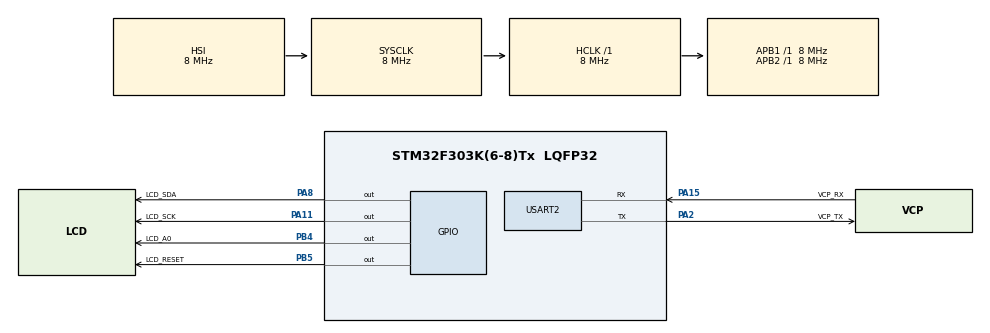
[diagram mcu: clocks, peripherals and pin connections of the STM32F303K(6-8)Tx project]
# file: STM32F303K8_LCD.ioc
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Mcu.Family=STM32F3
Mcu.Name=STM32F303K(6-8)Tx
Mcu.Package=LQFP32
NVIC.PriorityGroup=NVIC_PRIORITYGROUP_4
NVIC.TIM3_IRQn=true\:0\:0\:false\:false\:true\:true\:true
PA11.GPIO_Label=LCD_SCK
PA11.Signal=GPIO_Output
PA13.GPIO_Label=SWDIO
PA13.Mode=Serial_Wire
PA13.Signal=SYS_JTMS-SWDIO
PA14.GPIO_Label=SWCLK
PA14.Mode=Serial_Wire
PA14.Signal=SYS_JTCK-SWCLK
PA15.GPIO_Label=VCP_RX
PA15.Mode=Asynchronous
PA15.Signal=USART2_RX
PA2.GPIO_Label=VCP_TX
PA2.Mode=Asynchronous
PA2.Signal=USART2_TX
PA8.GPIO_Label=LCD_SDA
PA8.Signal=GPIO_Output
PB4.GPIO_Label=LCD_A0
PB4.Signal=GPIO_Output
PB5.GPIO_Label=LCD_RESET
PB5.Signal=GPIO_Output
PF0\ /\ OSC_IN.GPIO_Label=MCO
PF0\ /\ OSC_IN.Mode=HSE-External-Clock-Source
PF0\ /\ OSC_IN.Signal=RCC_OSC_IN
ProjectManager.HeapSize=0x200
ProjectManager.StackSize=0x400
ProjectManager.TargetToolchain=Makefile
RCC.AHBFreq_Value=8000000
RCC.APB1Freq_Value=8000000
RCC.APB2Freq_Value=8000000
RCC.CortexFreq_Value=8000000
RCC.HSE_VALUE=8000000
RCC.HSI_VALUE=8000000
RCC.SYSCLKFreq_VALUE=8000000
TIM1.Channel-Output\ Compare1\ No\ Output=TIM_CHANNEL_1
TIM3.Channel-Output\ Compare1\ No\ Output=TIM_CHANNEL_1
USART2.VirtualMode-Asynchronous=VM_ASYNC
VP_TIM1_VS_ClockSourceINT.Mode=Internal
VP_TIM1_VS_ClockSourceITR.Mode=TriggerSource_ITR0
VP_TIM1_VS_no_output1.Mode=Output Compare1 No Output
VP_TIM3_VS_ClockSourceINT.Mode=Internal
VP_TIM3_VS_no_output1.Mode=Output Compare1 No Output
board=NUCLEO-F303K8

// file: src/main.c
/* USER CODE BEGIN Header */
/**
  ******************************************************************************
  * @file           : main.c
  * @brief          : Main program body
  ******************************************************************************
  * @attention
  *
  * <h2><center>&copy; Copyright (c) 2020 STMicroelectronics.
  * All rights reserved.</center></h2>
  *
  * This software component is licensed by ST under BSD 3-Clause license,
  * the "License"; You may not use this file except in compliance with the
  * License. You may obtain a copy of the License at:
  *                        opensource.org/licenses/BSD-3-Clause
  *
  ******************************************************************************
  */
/* USER CODE END Header */

#include "main.h"

TIM_HandleTypeDef htim1;
TIM_HandleTypeDef htim3;

UART_HandleTypeDef huart2;

/* USER CODE BEGIN PV */
uint8_t led=0;
uint8_t scl=0;
uint8_t sda=0;
uint8_t pixy = 0;
uint8_t pixx = 0;
uint8_t csx = 1;
uint8_t pix_idx = 0;
uint8_t pix_buffer_idx = 0;
uint16_t pix_buffer=0;

/* USER CODE END PV */

void SystemClock_Config(void);
static void MX_GPIO_Init(void);
static void MX_TIM1_Init(void);
static void MX_USART2_UART_Init(void);
static void MX_TIM3_Init(void);

/* USER CODE BEGIN 0 */
// Definition of pixel info of color bar
PixInfo_t pixInfos0[] = { {160, 0x0} };
PixInfo_t pixInfos1[] = { {3, 0x0}, {22, 0xb5b6}, {22, 0xb5a1}, {22, 0xdb6}, {22, 0xda1}, {22, 0xb096}, {22, 0xb061}, {22, 0x876}, {3, 0x0} };
PixInfo_t pixInfos2[] = { {3, 0x0}, {22, 0x876}, {22, 0x1082}, {22, 0xb096}, {22, 0x1082}, {22, 0xdb6}, {22, 0x1082}, {22, 0xb5b6}, {3, 0x0} };
PixInfo_t pixInfos3[] = { {3, 0x0}, {27, 0x8e8}, {28, 0xef5d}, {27, 0x280b}, {28, 0x1082}, {7, 0x20}, {8, 0x1082}, {7, 0x18c3}, {22, 0x1082}, {3, 0x0} };
PixInfo_t pixInfos4[] = { {160, 0x0} };

LineInfo_t lineInfos[] = {{1, sizeof(pixInfos0)/sizeof(PixInfo_t), pixInfos0}, {84, sizeof(pixInfos1)/sizeof(PixInfo_t), pixInfos1}, {8, sizeof(pixInfos2)/sizeof(PixInfo_t), pixInfos2},{34, sizeof(pixInfos3)/sizeof(PixInfo_t), pixInfos3},{1, sizeof(pixInfos4)/sizeof(PixInfo_t), pixInfos4}};
/* USER CODE END 0 */

int main(void)
{

  /* MCU Configuration--------------------------------------------------------*/

  /* Reset of all peripherals, Initializes the Flash interface and the Systick. */
  HAL_Init();

  /* Configure the system clock */
  SystemClock_Config();

  /* Initialize all configured peripherals */
  MX_GPIO_Init();
  MX_TIM1_Init();
  MX_USART2_UART_Init();
  MX_TIM3_Init();
  /* USER CODE BEGIN 2 */
  HAL_TIM_Base_Start_IT(&htim3); // Begin timer(TMR3) interrupt
  /* disable it HAL_TIM_Base_Stop_IT(&htim3); */
  /* USER CODE END 2 */

  /* Infinite loop */
  while (1)
  {

  }
}

void SystemClock_Config(void)
{
  RCC_OscInitTypeDef RCC_OscInitStruct = {0};
  RCC_ClkInitTypeDef RCC_ClkInitStruct = {0};
  RCC_PeriphCLKInitTypeDef PeriphClkInit = {0};

  /** Initializes the CPU, AHB and APB busses clocks
  */
  RCC_OscInitStruct.OscillatorType = RCC_OSCILLATORTYPE_HSI;
  RCC_OscInitStruct.HSIState = RCC_HSI_ON;
  RCC_OscInitStruct.HSICalibrationValue = RCC_HSICALIBRATION_DEFAULT;
  RCC_OscInitStruct.PLL.PLLState = RCC_PLL_NONE;
  if (HAL_RCC_OscConfig(&RCC_OscInitStruct) != HAL_OK)
  {
    Error_Handler();
  }
  /** Initializes the CPU, AHB and APB busses clocks
  */
  RCC_ClkInitStruct.ClockType = RCC_CLOCKTYPE_HCLK|RCC_CLOCKTYPE_SYSCLK
                              |RCC_CLOCKTYPE_PCLK1|RCC_CLOCKTYPE_PCLK2;
  RCC_ClkInitStruct.SYSCLKSource = RCC_SYSCLKSOURCE_HSI;
  RCC_ClkInitStruct.AHBCLKDivider = RCC_SYSCLK_DIV1;
  RCC_ClkInitStruct.APB1CLKDivider = RCC_HCLK_DIV1;
  RCC_ClkInitStruct.APB2CLKDivider = RCC_HCLK_DIV1;

  if (HAL_RCC_ClockConfig(&RCC_ClkInitStruct, FLASH_LATENCY_0) != HAL_OK)
  {
    Error_Handler();
  }
  PeriphClkInit.PeriphClockSelection = RCC_PERIPHCLK_TIM1;
  PeriphClkInit.Tim1ClockSelection = RCC_TIM1CLK_HCLK;
  if (HAL_RCCEx_PeriphCLKConfig(&PeriphClkInit) != HAL_OK)
  {
    Error_Handler();
  }
}

static void MX_TIM1_Init(void)
{

  TIM_ClockConfigTypeDef sClockSourceConfig = {0};
  TIM_SlaveConfigTypeDef sSlaveConfig = {0};
  TIM_MasterConfigTypeDef sMasterConfig = {0};
  TIM_OC_InitTypeDef sConfigOC = {0};
  TIM_BreakDeadTimeConfigTypeDef sBreakDeadTimeConfig = {0};

  htim1.Instance = TIM1;
  htim1.Init.Prescaler = 0;
  htim1.Init.CounterMode = TIM_COUNTERMODE_UP;
  htim1.Init.Period = 0;
  htim1.Init.ClockDivision = TIM_CLOCKDIVISION_DIV1;
  htim1.Init.RepetitionCounter = 0;
  htim1.Init.AutoReloadPreload = TIM_AUTORELOAD_PRELOAD_DISABLE;
  if (HAL_TIM_Base_Init(&htim1) != HAL_OK)
  {
    Error_Handler();
  }
  sClockSourceConfig.ClockSource = TIM_CLOCKSOURCE_INTERNAL;
  if (HAL_TIM_ConfigClockSource(&htim1, &sClockSourceConfig) != HAL_OK)
  {
    Error_Handler();
  }
  if (HAL_TIM_OC_Init(&htim1) != HAL_OK)
  {
    Error_Handler();
  }
  sSlaveConfig.SlaveMode = TIM_SLAVEMODE_DISABLE;
  sSlaveConfig.InputTrigger = TIM_TS_ITR0;
  if (HAL_TIM_SlaveConfigSynchro(&htim1, &sSlaveConfig) != HAL_OK)
  {
    Error_Handler();
  }
  sMasterConfig.MasterOutputTrigger = TIM_TRGO_RESET;
  sMasterConfig.MasterOutputTrigger2 = TIM_TRGO2_RESET;
  sMasterConfig.MasterSlaveMode = TIM_MASTERSLAVEMODE_DISABLE;
  if (HAL_TIMEx_MasterConfigSynchronization(&htim1, &sMasterConfig) != HAL_OK)
  {
    Error_Handler();
  }
  sConfigOC.OCMode = TIM_OCMODE_TIMING;
  sConfigOC.Pulse = 0;
  sConfigOC.OCPolarity = TIM_OCPOLARITY_HIGH;
  sConfigOC.OCNPolarity = TIM_OCNPOLARITY_HIGH;
  sConfigOC.OCFastMode = TIM_OCFAST_DISABLE;
  sConfigOC.OCIdleState = TIM_OCIDLESTATE_RESET;
  sConfigOC.OCNIdleState = TIM_OCNIDLESTATE_RESET;
  if (HAL_TIM_OC_ConfigChannel(&htim1, &sConfigOC, TIM_CHANNEL_1) != HAL_OK)
  {
    Error_Handler();
  }
  sBreakDeadTimeConfig.OffStateRunMode = TIM_OSSR_DISABLE;
  sBreakDeadTimeConfig.OffStateIDLEMode = TIM_OSSI_DISABLE;
  sBreakDeadTimeConfig.LockLevel = TIM_LOCKLEVEL_OFF;
  sBreakDeadTimeConfig.DeadTime = 0;
  sBreakDeadTimeConfig.BreakState = TIM_BREAK_DISABLE;
  sBreakDeadTimeConfig.BreakPolarity = TIM_BREAKPOLARITY_HIGH;
  sBreakDeadTimeConfig.BreakFilter = 0;
  sBreakDeadTimeConfig.Break2State = TIM_BREAK2_DISABLE;
  sBreakDeadTimeConfig.Break2Polarity = TIM_BREAK2POLARITY_HIGH;
  sBreakDeadTimeConfig.Break2Filter = 0;
  sBreakDeadTimeConfig.AutomaticOutput = TIM_AUTOMATICOUTPUT_DISABLE;
  if (HAL_TIMEx_ConfigBreakDeadTime(&htim1, &sBreakDeadTimeConfig) != HAL_OK)
  {
    Error_Handler();
  }

}

static void MX_TIM3_Init(void)
{

  TIM_ClockConfigTypeDef sClockSourceConfig = {0};
  TIM_MasterConfigTypeDef sMasterConfig = {0};
  TIM_OC_InitTypeDef sConfigOC = {0};

  htim3.Instance = TIM3;
  htim3.Init.Prescaler = 7999;
  htim3.Init.CounterMode = TIM_COUNTERMODE_UP;
  htim3.Init.Period = 999;
  htim3.Init.ClockDivision = TIM_CLOCKDIVISION_DIV1;
  htim3.Init.AutoReloadPreload = TIM_AUTORELOAD_PRELOAD_DISABLE;
  if (HAL_TIM_Base_Init(&htim3) != HAL_OK)
  {
    Error_Handler();
  }
  sClockSourceConfig.ClockSource = TIM_CLOCKSOURCE_INTERNAL;
  if (HAL_TIM_ConfigClockSource(&htim3, &sClockSourceConfig) != HAL_OK)
  {
    Error_Handler();
  }
  if (HAL_TIM_OC_Init(&htim3) != HAL_OK)
  {
    Error_Handler();
  }
  sMasterConfig.MasterOutputTrigger = TIM_TRGO_RESET;
  sMasterConfig.MasterSlaveMode = TIM_MASTERSLAVEMODE_DISABLE;
  if (HAL_TIMEx_MasterConfigSynchronization(&htim3, &sMasterConfig) != HAL_OK)
  {
    Error_Handler();
  }
  sConfigOC.OCMode = TIM_OCMODE_TIMING;
  sConfigOC.Pulse = 0;
  sConfigOC.OCPolarity = TIM_OCPOLARITY_HIGH;
  sConfigOC.OCFastMode = TIM_OCFAST_DISABLE;
  if (HAL_TIM_OC_ConfigChannel(&htim3, &sConfigOC, TIM_CHANNEL_1) != HAL_OK)
  {
    Error_Handler();
  }

}

static void MX_USART2_UART_Init(void)
{

  huart2.Instance = USART2;
  huart2.Init.BaudRate = 38400;
  huart2.Init.WordLength = UART_WORDLENGTH_8B;
  huart2.Init.StopBits = UART_STOPBITS_1;
  huart2.Init.Parity = UART_PARITY_NONE;
  huart2.Init.Mode = UART_MODE_TX_RX;
  huart2.Init.HwFlowCtl = UART_HWCONTROL_NONE;
  huart2.Init.OverSampling = UART_OVERSAMPLING_16;
  huart2.Init.OneBitSampling = UART_ONE_BIT_SAMPLE_DISABLE;
  huart2.AdvancedInit.AdvFeatureInit = UART_ADVFEATURE_NO_INIT;
  if (HAL_UART_Init(&huart2) != HAL_OK)
  {
    Error_Handler();
  }

}

static void MX_GPIO_Init(void)
{
  GPIO_InitTypeDef GPIO_InitStruct = {0};

  /* GPIO Ports Clock Enable */
  __HAL_RCC_GPIOF_CLK_ENABLE();
  __HAL_RCC_GPIOA_CLK_ENABLE();
  __HAL_RCC_GPIOB_CLK_ENABLE();

  /*Configure GPIO pin Output Level */
  HAL_GPIO_WritePin(GPIOA, LCD_SDA_Pin|LCD_SCK_Pin, GPIO_PIN_RESET);

  /*Configure GPIO pin Output Level */
  HAL_GPIO_WritePin(GPIOB, LCD_A0_Pin|LCD_RESET_Pin|GPIO_PIN_3, GPIO_PIN_RESET);

  /*Configure GPIO pins : LCD_SDA_Pin LCD_SCK_Pin */
  GPIO_InitStruct.Pin = LCD_SDA_Pin|LCD_SCK_Pin;
  GPIO_InitStruct.Mode = GPIO_MODE_OUTPUT_PP;
  GPIO_InitStruct.Pull = GPIO_NOPULL;
  GPIO_InitStruct.Speed = GPIO_SPEED_FREQ_LOW;
  HAL_GPIO_Init(GPIOA, &GPIO_InitStruct);

  /*Configure GPIO pins : LCD_A0_Pin LCD_RESET_Pin */
  GPIO_InitStruct.Pin = LCD_A0_Pin|LCD_RESET_Pin|GPIO_PIN_3;
  GPIO_InitStruct.Mode = GPIO_MODE_OUTPUT_PP;
  GPIO_InitStruct.Pull = GPIO_NOPULL;
  GPIO_InitStruct.Speed = GPIO_SPEED_FREQ_LOW;
  HAL_GPIO_Init(GPIOB, &GPIO_InitStruct);

}

void Error_Handler(void)
{
}

/************************ (C) COPYRIGHT STMicroelectronics *****END OF FILE****/
